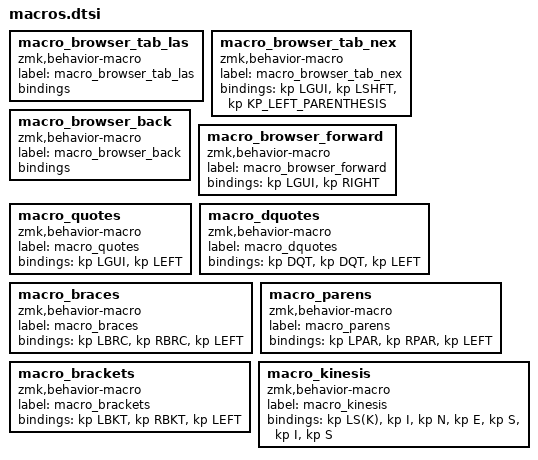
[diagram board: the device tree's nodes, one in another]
macro_browser_tab_las: macro_browser_tab_las{
compatible = "zmk,behavior-macro";
label = "macro_browser_tab_las";
#binding-cells = <0>;
bindings = ;
};
macro_browser_tab_nex: macro_browser_tab_nex{
compatible = "zmk,behavior-macro";
label = "macro_browser_tab_nex";
#binding-cells = <0>;
bindings = <&kp LGUI>, <&kp LSHFT>, <&kp KP_LEFT_PARENTHESIS>;
};
macro_browser_back: macro_browser_back{
compatible = "zmk,behavior-macro";
label = "macro_browser_back";
#binding-cells = <0>;
bindings = ;
};
macro_browser_forward: macro_browser_forward{
compatible = "zmk,behavior-macro";
label = "macro_browser_forward";
#binding-cells = <0>;
bindings = <&kp LGUI>, <&kp RIGHT>;
};
macro_quotes: macro_quotes{
compatible = "zmk,behavior-macro";
label = "macro_quotes";
#binding-cells = <0>;
bindings = <&kp LGUI>, <&kp LEFT>;
};
macro_dquotes: macro_dquotes{
compatible = "zmk,behavior-macro";
label = "macro_dquotes";
#binding-cells = <0>;
bindings = <&kp DQT>, <&kp DQT>, <&kp LEFT>;
};
macro_braces: macro_braces{
compatible = "zmk,behavior-macro";
label = "macro_braces";
#binding-cells = <0>;
bindings = <&kp LBRC>, <&kp RBRC>, <&kp LEFT>;
};
macro_parens: macro_parens{
compatible = "zmk,behavior-macro";
label = "macro_parens";
#binding-cells = <0>;
bindings = <&kp LPAR>, <&kp RPAR>, <&kp LEFT>;
};
macro_brackets: macro_brackets{
compatible = "zmk,behavior-macro";
label = "macro_brackets";
#binding-cells = <0>;
bindings = <&kp LBKT>, <&kp RBKT>, <&kp LEFT>;
};
macro_kinesis: macro_kinesis{
compatible = "zmk,behavior-macro";
label = "macro_kinesis";
#binding-cells = <0>;
bindings = <&kp LS(K)>, <&kp I>, <&kp N>, <&kp E>, <&kp S>, <&kp I>, <&kp S>;
};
